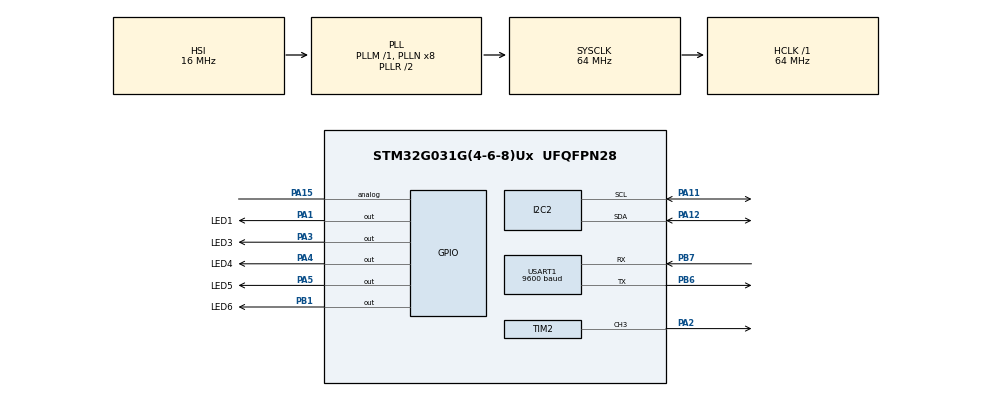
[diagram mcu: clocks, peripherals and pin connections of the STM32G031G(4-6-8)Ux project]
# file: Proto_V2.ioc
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I2C2.I2C_Fall_Time=10
I2C2.I2C_Rise_Time=10
I2C2.Speed=50
I2C2.Timing=0x304048F3
Mcu.Family=STM32G0
Mcu.Name=STM32G031G(4-6-8)Ux
Mcu.Package=UFQFPN28
NVIC.USART1_IRQn=true\:0\:0\:false\:false\:true\:true\:true\:true
PA0.Signal=SYS_WKUP1
PA1.GPIO_Label=LED1
PA1.Signal=GPIO_Output
PA11\ [PA9].GPIO_Pu=GPIO_NOPULL
PA11\ [PA9].GPIO_Speed=GPIO_SPEED_FREQ_MEDIUM
PA11\ [PA9].Mode=I2C
PA11\ [PA9].PinState=GPIO_PIN_RESET
PA11\ [PA9].Signal=I2C2_SCL
PA12\ [PA10].GPIO_Pu=GPIO_NOPULL
PA12\ [PA10].GPIO_Speed=GPIO_SPEED_FREQ_MEDIUM
PA12\ [PA10].Mode=I2C
PA12\ [PA10].PinState=GPIO_PIN_RESET
PA12\ [PA10].Signal=I2C2_SDA
PA13.Mode=Serial_Wire
PA13.Signal=SYS_SWDIO
PA14-BOOT0.Mode=Serial_Wire
PA14-BOOT0.Signal=SYS_SWCLK
PA15.Signal=GPIO_Analog
PA2.Signal=S_TIM2_CH3
PA3.GPIO_Label=LED3
PA3.Signal=GPIO_Output
PA4.GPIO_Label=LED4
PA4.Signal=GPIO_Output
PA5.GPIO_Label=LED5
PA5.Signal=GPIO_Output
PA6.Signal=SPI1_MISO
PA7.Signal=SPI1_MOSI
PB0.Signal=SPI1_NSS
PB1.GPIO_Label=LED6
PB1.Signal=GPIO_Output
PB3.Signal=SPI1_SCK
PB6.Mode=Asynchronous
PB6.Signal=USART1_TX
PB7.Mode=Asynchronous
PB7.Signal=USART1_RX
PC14-OSC32_IN\ (PC14).Mode=LSE-External-Oscillator
PC14-OSC32_IN\ (PC14).Signal=RCC_OSC32_IN
PC15-OSC32_OUT\ (PC15).Mode=LSE-External-Oscillator
PC15-OSC32_OUT\ (PC15).Signal=RCC_OSC32_OUT
ProjectManager.HeapSize=0x200
ProjectManager.StackSize=0x400
ProjectManager.TargetToolchain=STM32CubeIDE
RCC.ADCFreq_Value=64000000
RCC.AHBFreq_Value=64000000
RCC.CortexFreq_Value=64000000
RCC.EXTERNAL_CLOCK_VALUE=12288000
RCC.HCLKFreq_Value=64000000
RCC.HSE_VALUE=8000000
RCC.HSI_VALUE=16000000
RCC.SYSCLKFreq_VALUE=64000000
RCC.SYSCLKSource=RCC_SYSCLKSOURCE_PLLCLK
RCC.VCOOutputFreq_Value=128000000
SH.S_TIM2_CH3.0=TIM2_CH3,PWM Generation3 CH3
TIM2.AutoReloadPreload=TIM_AUTORELOAD_PRELOAD_DISABLE
TIM2.Channel-PWM\ Generation3\ CH3=TIM_CHANNEL_3
TIM2.Period=255
TIM2.Pulse-PWM\ Generation3\ CH3=15
USART1.BaudRate=9600
USART1.VirtualMode-Asynchronous=VM_ASYNC
board=custom

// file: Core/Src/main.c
/* USER CODE BEGIN Header */
/**
  ******************************************************************************
  * @file           : main.c
  * @brief          : Main program body
  ******************************************************************************
  * @attention
  *
  * Copyright (c) 2024 STMicroelectronics.
  * All rights reserved.
  *
  * This software is licensed under terms that can be found in the LICENSE file
  * in the root directory of this software component.
  * If no LICENSE file comes with this software, it is provided AS-IS.
  *
  ******************************************************************************
  */
/* USER CODE END Header */
#include "main.h"

/* USER CODE BEGIN Includes */
#include "STM32_IMU.h"
#include "stdio.h"
#include "PWM.h"
/* USER CODE END Includes */

/* USER CODE BEGIN PD */
#define PUTCHAR_PROTOTYPE int __io_putchar(int ch)
/* USER CODE END PD */

I2C_HandleTypeDef hi2c2;

TIM_HandleTypeDef htim2;

UART_HandleTypeDef huart1;

void SystemClock_Config(void);
static void MX_GPIO_Init(void);
static void MX_TIM2_Init(void);
static void MX_I2C2_Init(void);
static void MX_USART1_UART_Init(void);

int main(void)
{

  /* MCU Configuration--------------------------------------------------------*/

  /* Reset of all peripherals, Initializes the Flash interface and the Systick. */
  HAL_Init();

  /* Configure the system clock */
  SystemClock_Config();

  /* Initialize all configured peripherals */
  MX_GPIO_Init();
  MX_TIM2_Init();
  MX_I2C2_Init();
  MX_USART1_UART_Init();
  /* USER CODE BEGIN 2 */
  init_IMU_MPU6050();
  /* USER CODE END 2 */

  /* Infinite loop */
  /* USER CODE BEGIN WHILE */
  while (1)
  {

	  read_IMU_temp();
	  Read_IMU_Gyro();
//	  LED_pwm();

	  }
  }
    /* USER CODE END WHILE */

    /* USER CODE BEGIN 3 */
//PUTCHAR_PROTOTYPE
//{
//  /* Place your implementation of fputc here */
//  /* e.g. write a character to the USART1 and Loop until the end of transmission */
//  HAL_UART_Transmit(&huart1, (uint8_t *)&ch, 1, 0xFFFF);
//
//  return ch;
//}
    /* USER CODE END WHILE */

    /* USER CODE BEGIN 3 */

  /* USER CODE END 3 */

void SystemClock_Config(void)
{
  RCC_OscInitTypeDef RCC_OscInitStruct = {0};
  RCC_ClkInitTypeDef RCC_ClkInitStruct = {0};

  /** Configure the main internal regulator output voltage
  */
  HAL_PWREx_ControlVoltageScaling(PWR_REGULATOR_VOLTAGE_SCALE1);

  /** Initializes the RCC Oscillators according to the specified parameters
  * in the RCC_OscInitTypeDef structure.
  */
  RCC_OscInitStruct.OscillatorType = RCC_OSCILLATORTYPE_HSI;
  RCC_OscInitStruct.HSIState = RCC_HSI_ON;
  RCC_OscInitStruct.HSIDiv = RCC_HSI_DIV1;
  RCC_OscInitStruct.HSICalibrationValue = RCC_HSICALIBRATION_DEFAULT;
  RCC_OscInitStruct.PLL.PLLState = RCC_PLL_ON;
  RCC_OscInitStruct.PLL.PLLSource = RCC_PLLSOURCE_HSI;
  RCC_OscInitStruct.PLL.PLLM = RCC_PLLM_DIV1;
  RCC_OscInitStruct.PLL.PLLN = 8;
  RCC_OscInitStruct.PLL.PLLP = RCC_PLLP_DIV2;
  RCC_OscInitStruct.PLL.PLLQ = RCC_PLLQ_DIV2;
  RCC_OscInitStruct.PLL.PLLR = RCC_PLLR_DIV2;
  if (HAL_RCC_OscConfig(&RCC_OscInitStruct) != HAL_OK)
  {
    Error_Handler();
  }

  /** Initializes the CPU, AHB and APB buses clocks
  */
  RCC_ClkInitStruct.ClockType = RCC_CLOCKTYPE_HCLK|RCC_CLOCKTYPE_SYSCLK
                              |RCC_CLOCKTYPE_PCLK1;
  RCC_ClkInitStruct.SYSCLKSource = RCC_SYSCLKSOURCE_PLLCLK;
  RCC_ClkInitStruct.AHBCLKDivider = RCC_SYSCLK_DIV1;
  RCC_ClkInitStruct.APB1CLKDivider = RCC_HCLK_DIV1;

  if (HAL_RCC_ClockConfig(&RCC_ClkInitStruct, FLASH_LATENCY_2) != HAL_OK)
  {
    Error_Handler();
  }
}

static void MX_I2C2_Init(void)
{

  /* USER CODE BEGIN I2C2_Init 1 */
//	RCC->APBENR1 |= (1<<22);  // enable I2C CLOCK
  /* USER CODE END I2C2_Init 1 */
  hi2c2.Instance = I2C2;
  hi2c2.Init.Timing = 0x304048F3;
  hi2c2.Init.OwnAddress1 = 0;
  hi2c2.Init.AddressingMode = I2C_ADDRESSINGMODE_7BIT;
  hi2c2.Init.DualAddressMode = I2C_DUALADDRESS_DISABLE;
  hi2c2.Init.OwnAddress2 = 0;
  hi2c2.Init.OwnAddress2Masks = I2C_OA2_NOMASK;
  hi2c2.Init.GeneralCallMode = I2C_GENERALCALL_DISABLE;
  hi2c2.Init.NoStretchMode = I2C_NOSTRETCH_DISABLE;
  if (HAL_I2C_Init(&hi2c2) != HAL_OK)
  {
    Error_Handler();
  }

  /** Configure Analogue filter
  */
  if (HAL_I2CEx_ConfigAnalogFilter(&hi2c2, I2C_ANALOGFILTER_ENABLE) != HAL_OK)
  {
    Error_Handler();
  }

  /** Configure Digital filter
  */
  if (HAL_I2CEx_ConfigDigitalFilter(&hi2c2, 0) != HAL_OK)
  {
    Error_Handler();
  }

}

static void MX_TIM2_Init(void)
{

  TIM_MasterConfigTypeDef sMasterConfig = {0};
  TIM_OC_InitTypeDef sConfigOC = {0};

  htim2.Instance = TIM2;
  htim2.Init.Prescaler = 0;
  htim2.Init.CounterMode = TIM_COUNTERMODE_UP;
  htim2.Init.Period = 255;
  htim2.Init.ClockDivision = TIM_CLOCKDIVISION_DIV1;
  htim2.Init.AutoReloadPreload = TIM_AUTORELOAD_PRELOAD_DISABLE;
  if (HAL_TIM_PWM_Init(&htim2) != HAL_OK)
  {
    Error_Handler();
  }
  sMasterConfig.MasterOutputTrigger = TIM_TRGO_RESET;
  sMasterConfig.MasterSlaveMode = TIM_MASTERSLAVEMODE_DISABLE;
  if (HAL_TIMEx_MasterConfigSynchronization(&htim2, &sMasterConfig) != HAL_OK)
  {
    Error_Handler();
  }
  sConfigOC.OCMode = TIM_OCMODE_PWM1;
  sConfigOC.Pulse = 15;
  sConfigOC.OCPolarity = TIM_OCPOLARITY_HIGH;
  sConfigOC.OCFastMode = TIM_OCFAST_DISABLE;
  if (HAL_TIM_PWM_ConfigChannel(&htim2, &sConfigOC, TIM_CHANNEL_3) != HAL_OK)
  {
    Error_Handler();
  }
  /* USER CODE BEGIN TIM2_Init 2 */

  HAL_TIM_Base_Start(&htim2);
  HAL_TIM_PWM_Start(&htim2, TIM_CHANNEL_3);

  /* USER CODE END TIM2_Init 2 */
  HAL_TIM_MspPostInit(&htim2);

}

static void MX_USART1_UART_Init(void)
{

  huart1.Instance = USART1;
  huart1.Init.BaudRate = 9600;
  huart1.Init.WordLength = UART_WORDLENGTH_8B;
  huart1.Init.StopBits = UART_STOPBITS_1;
  huart1.Init.Parity = UART_PARITY_NONE;
  huart1.Init.Mode = UART_MODE_TX_RX;
  huart1.Init.HwFlowCtl = UART_HWCONTROL_NONE;
  huart1.Init.OverSampling = UART_OVERSAMPLING_16;
  huart1.Init.OneBitSampling = UART_ONE_BIT_SAMPLE_DISABLE;
  huart1.Init.ClockPrescaler = UART_PRESCALER_DIV1;
  huart1.AdvancedInit.AdvFeatureInit = UART_ADVFEATURE_NO_INIT;
  if (HAL_UART_Init(&huart1) != HAL_OK)
  {
    Error_Handler();
  }
  if (HAL_UARTEx_SetTxFifoThreshold(&huart1, UART_TXFIFO_THRESHOLD_1_8) != HAL_OK)
  {
    Error_Handler();
  }
  if (HAL_UARTEx_SetRxFifoThreshold(&huart1, UART_RXFIFO_THRESHOLD_1_8) != HAL_OK)
  {
    Error_Handler();
  }
  if (HAL_UARTEx_DisableFifoMode(&huart1) != HAL_OK)
  {
    Error_Handler();
  }

}

static void MX_GPIO_Init(void)
{
  GPIO_InitTypeDef GPIO_InitStruct = {0};

  /* GPIO Ports Clock Enable */
  __HAL_RCC_GPIOC_CLK_ENABLE();
  __HAL_RCC_GPIOA_CLK_ENABLE();
  __HAL_RCC_GPIOB_CLK_ENABLE();

  /*Configure GPIO pin Output Level */
  HAL_GPIO_WritePin(GPIOA, LED1_Pin|LED3_Pin|LED4_Pin|LED5_Pin, GPIO_PIN_RESET);

  /*Configure GPIO pin Output Level */
  HAL_GPIO_WritePin(LED6_GPIO_Port, LED6_Pin, GPIO_PIN_RESET);

  /*Configure GPIO pins : LED1_Pin LED3_Pin LED4_Pin LED5_Pin */
  GPIO_InitStruct.Pin = LED1_Pin|LED3_Pin|LED4_Pin|LED5_Pin;
  GPIO_InitStruct.Mode = GPIO_MODE_OUTPUT_PP;
  GPIO_InitStruct.Pull = GPIO_NOPULL;
  GPIO_InitStruct.Speed = GPIO_SPEED_FREQ_LOW;
  HAL_GPIO_Init(GPIOA, &GPIO_InitStruct);

  /*Configure GPIO pins : PA6 PA7 */
  GPIO_InitStruct.Pin = GPIO_PIN_6|GPIO_PIN_7;
  GPIO_InitStruct.Mode = GPIO_MODE_AF_PP;
  GPIO_InitStruct.Pull = GPIO_NOPULL;
  GPIO_InitStruct.Speed = GPIO_SPEED_FREQ_LOW;
  GPIO_InitStruct.Alternate = GPIO_AF0_SPI1;
  HAL_GPIO_Init(GPIOA, &GPIO_InitStruct);

  /*Configure GPIO pins : PB0 PB3 */
  GPIO_InitStruct.Pin = GPIO_PIN_0|GPIO_PIN_3;
  GPIO_InitStruct.Mode = GPIO_MODE_AF_PP;
  GPIO_InitStruct.Pull = GPIO_NOPULL;
  GPIO_InitStruct.Speed = GPIO_SPEED_FREQ_LOW;
  GPIO_InitStruct.Alternate = GPIO_AF0_SPI1;
  HAL_GPIO_Init(GPIOB, &GPIO_InitStruct);

  /*Configure GPIO pin : LED6_Pin */
  GPIO_InitStruct.Pin = LED6_Pin;
  GPIO_InitStruct.Mode = GPIO_MODE_OUTPUT_PP;
  GPIO_InitStruct.Pull = GPIO_NOPULL;
  GPIO_InitStruct.Speed = GPIO_SPEED_FREQ_LOW;
  HAL_GPIO_Init(LED6_GPIO_Port, &GPIO_InitStruct);

  /*Configure GPIO pin : PA15 */
  GPIO_InitStruct.Pin = GPIO_PIN_15;
  GPIO_InitStruct.Mode = GPIO_MODE_ANALOG;
  GPIO_InitStruct.Pull = GPIO_NOPULL;
  HAL_GPIO_Init(GPIOA, &GPIO_InitStruct);

}

void Error_Handler(void)
{
  __disable_irq();
  while (1)
  {
  }
}
